# STM32F031C4T6 register map
File version: 1.0
Registers are 32-bit, access not given, reset 0x0 unless marked. A register's access mark holds for its fields unless they carry their own. Offsets are from the block's base; [hi:lo] are bit positions; {n}, {i} and the like mark numbered series.

## I2C1
Base 0x40005400
Same registers: I2C2 0x40005800
0x00 CR1
  [23] PECEN, [22] ALERTEN, [21] SMBDEN, [20] SMBHEN, [19] GCEN, [18] WUPEN, [17] NOSTRETCH, [16] SBC, [15] RXDMAEN, [14] TXDMAEN, [31:13] s, [12] ANFOFF, [11:8] DNF, [7] ERRIE, [6] TCIE, [5] STOPIE, [4] NACKIE, [3] ADDRIE, [2] RXIE, [1] TXIE, [0] PE
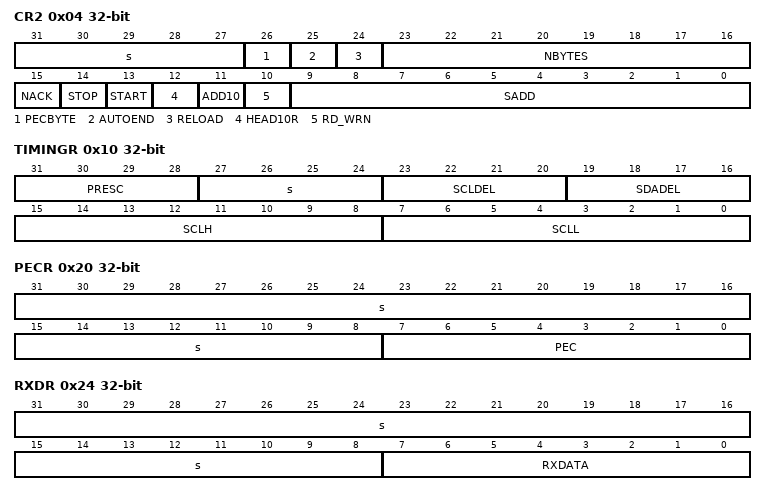
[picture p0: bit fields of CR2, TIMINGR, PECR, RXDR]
0x04 CR2
  [31:27] s, [26] PECBYTE, [25] AUTOEND, [24] RELOAD, [23:16] NBYTES, [15] NACK, [14] STOP, [13] START, [12] HEAD10R, [11] ADD10, [10] RD_WRN, [9:0] SADD
0x08 OAR1
  [15] OA1EN, [31:11] s, [10] OA1MODE, [9:0] OA1
0x0C OAR2
  [15] OA2EN, [10:8] OA2MSK, [7:1] OA2, [31:0] s
0x10 TIMINGR
  [31:28] PRESC, [27:24] s, [23:20] SCLDEL, [19:16] SDADEL, [15:8] SCLH, [7:0] SCLL
0x14 TIMEOUTR
  [31] TEXTEN, [27:16] TIMEOUTB, [15] TIMOUTEN, [30:13] s, [12] TIDLE, [11:0] TIMEOUTA
0x18 ISR
  [23:17] ADDCODE, [16] DIR, [15] BUSY, [31:14] s, [13] ALERT, [12] TIMEOUT, [11] PECERR, [10] OVR, [9] ARLO, [8] BERR, [7] TCR, [6] TC, [5] STOPF, [4] NACKF, [3] ADDR, [2] RXNE, [1] TXIS, [0] TXE
0x1C ICR
  [13] ALERTCF, [12] TIMOUTCF, [11] PECCF, [10] OVRCF, [9] ARLOCF, [8] BERRCF, [5] STOPCF, [4] NACKCF, [3] ADDRCF, [31:0] s
0x20 PECR
  [31:8] s, [7:0] PEC
0x24 RXDR
  [31:8] s, [7:0] RXDATA
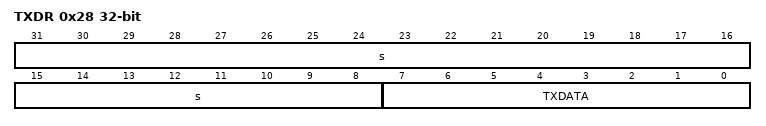
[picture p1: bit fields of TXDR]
0x28 TXDR
  [31:8] s, [7:0] TXDATA

## USB
Base 0x40005C00
Same registers: USB 0x40006000, USB 0x40006000
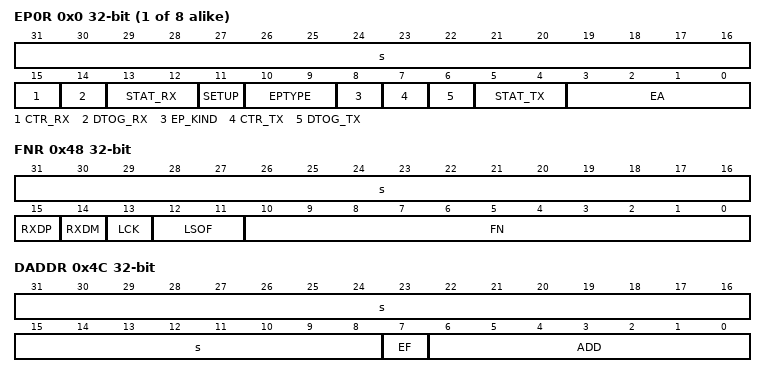
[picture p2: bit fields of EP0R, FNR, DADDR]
{0x0+4i} EP{i}R (i=0..7)
  [31:16] s, [15] CTR_RX, [14] DTOG_RX, [13:12] STAT_RX, [11] SETUP, [10:9] EPTYPE, [8] EP_KIND, [7] CTR_TX, [6] DTOG_TX, [5:4] STAT_TX, [3:0] EA
0x40 CNTR
  [15] CTRM, [14] PMAOVRM, [13] ERRM, [12] WKUPM, [11] SUSPM, [10] RESETM, [9] SOFM, [8] ESOFM, [7] L1REQM, [31:6] s, [5] L1RESUME, [4] RESUME, [3] FSUSP, [2] LPMODE, [1] PDWN, [0] FRES
0x44 ISTR
  [15] CTR, [14] PMAOVR, [13] ERR, [12] WKUP, [11] SUSP, [10] RESET, [9] SOF, [8] ESOF, [7] L1REQ, [31:5] s, [4] DIR, [3:0] EP_ID
0x48 FNR
  [31:16] s, [15] RXDP, [14] RXDM, [13] LCK, [12:11] LSOF, [10:0] FN
0x4C DADDR
  [31:8] s, [7] EF, [6:0] ADD
0x50 BTABLE
  [15:3] BTABLE, [31:0] s
0x54 LPMCSR
  [7:4] BESL, [3] REMWAKE, [31:2] s, [1] LPMACK, [0] LPMEN
0x58 BCDR
  [15] DPPU, [31:8] s, [7] PS2DET, [6] SDET, [5] PDET, [4] DCDET, [3] SDEN, [2] PDEN, [1] DCDEN, [0] BCDEN

## CANSRAM
Base 0x40006000
Same registers: CAN 0x40006400
0x00 MCR
  [16] DBF, [15] RESET, [31:8] s, [7] TTCM, [6] ABOM, [5] AWUM, [4] NART, [3] RFLM, [2] TXFP, [1] SLEEP, [0] INRQ
0x04 MSR
  [11] RX, [10] SAMP, [9] RXM, [8] TXM, [31:5] s, [4] SLAKI, [3] WKUI, [2] ERRI, [1] SLAK, [0] INAK
0x08 TSR
  [31:29] LOW, [28:26] TME, [25:24] CODE, [23] ABRQ2, [19] TERR2, [18] ALST2, [17] TXOK2, [16] RQCP2, [15] ABRQ1, [11] TERR1, [10] ALST1, [9] TXOK1, [8] RQCP1, [7] ABRQ0, [22:4] s, [3] TERR0, [2] ALST0, [1] TXOK0, [0] RQCP0
0x0C RF0R
  [5] RFOM0, [4] FOVR0, [3] FULL0, [31:2] s, [1:0] FMP0
0x10 RF1R
  [5] RFOM1, [4] FOVR1, [3] FULL1, [31:2] s, [1:0] FMP1
0x14 IER
  [17] SLKIE, [16] WKUIE, [15] ERRIE, [11] LECIE, [10] BOFIE, [9] EPVIE, [8] EWGIE, [31:7] s, [6] FOVIE1, [5] FFIE1, [4] FMPIE1, [3] FOVIE0, [2] FFIE0, [1] FMPIE0, [0] TMEIE
0x18 ESR
  [31:24] REC, [23:16] TEC, [6:4] LEC, [15:3] s, [2] BOFF, [1] EPVF, [0] EWGF
0x1C BTR
  [31] SILM, [30] LBKM, [25:24] SJW, [22:20] TS2, [19:16] TS1, [29:10] s, [9:0] BRP
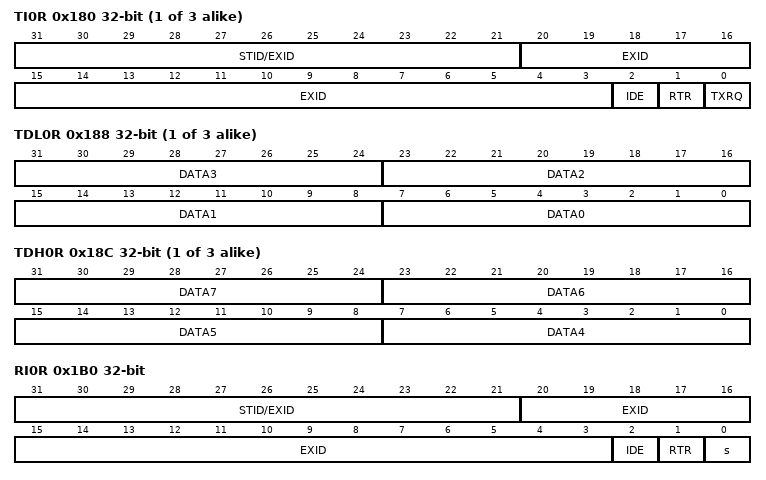
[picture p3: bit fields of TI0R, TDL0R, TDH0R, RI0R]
{0x180+0x10*i} TI{i}R (i=0..2)
  [31:21] STID/EXID, [20:3] EXID, [2] IDE, [1] RTR, [0] TXRQ
{0x184+0x10*i} TDT{i}R (i=0..2)
  [31:16] TIME, [8] TGT, [15:4] s, [3:0] DLC
{0x188+0x10*i} TDL{i}R (i=0..2)
  [8n+7:8n] DATA{n} (n=0..3)
{0x18C+0x10*i} TDH{i}R (i=0..2)
  [8n-25:8n-32] DATA{n} (n=4..7)
0x1B0 RI0R
  [31:21] STID/EXID, [20:3] EXID, [2] IDE, [1] RTR, [0] s
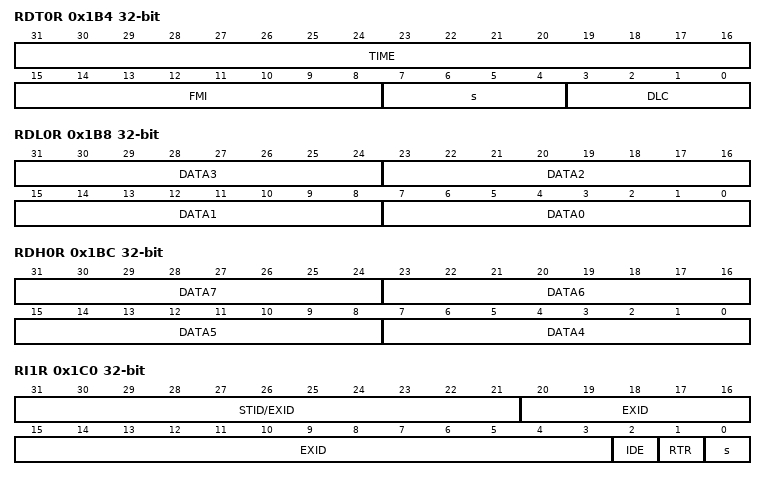
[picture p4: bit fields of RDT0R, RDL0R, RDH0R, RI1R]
0x1B4 RDT0R
  [31:16] TIME, [15:8] FMI, [7:4] s, [3:0] DLC
0x1B8 RDL0R
  [8n+7:8n] DATA{n} (n=0..3)
0x1BC RDH0R
  [8n-25:8n-32] DATA{n} (n=4..7)
0x1C0 RI1R
  [31:21] STID/EXID, [20:3] EXID, [2] IDE, [1] RTR, [0] s
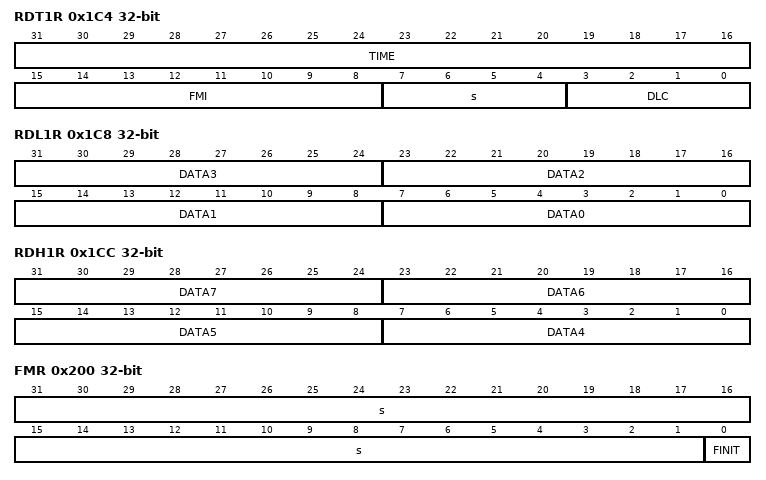
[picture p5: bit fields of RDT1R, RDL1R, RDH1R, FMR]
0x1C4 RDT1R
  [31:16] TIME, [15:8] FMI, [7:4] s, [3:0] DLC
0x1C8 RDL1R
  [8n+7:8n] DATA{n} (n=0..3)
0x1CC RDH1R
  [8n-25:8n-32] DATA{n} (n=4..7)
0x200 FMR
  [31:1] s, [0] FINIT
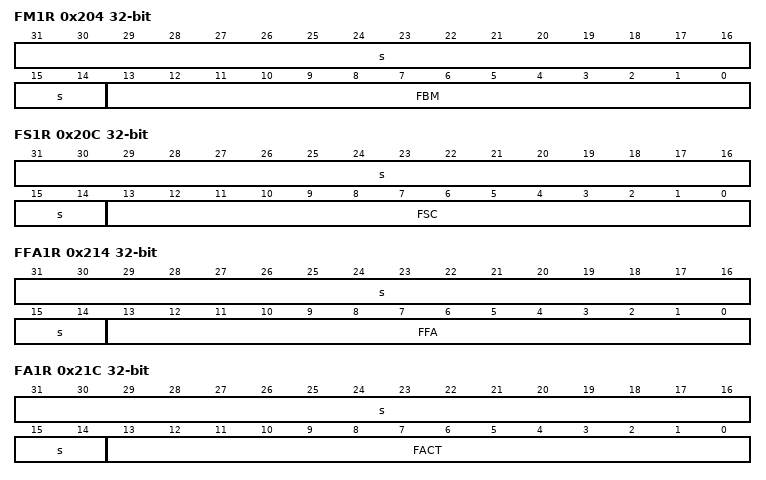
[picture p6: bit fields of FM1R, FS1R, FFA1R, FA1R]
0x204 FM1R
  [31:14] s, [13:0] FBM
0x20C FS1R
  [31:14] s, [13:0] FSC
0x214 FFA1R
  [31:14] s, [13:0] FFA
0x21C FA1R
  [31:14] s, [13:0] FACT
0x240 F0R1
  [31:0] FB
0x244 F0R2
  [31:0] FB
0x248 F1R1
  [31:0] FB
0x24C F1R2
  [31:0] FB
0x318 F27R1
  [31:0] FB
0x31C F27R2
  [31:0] FB
